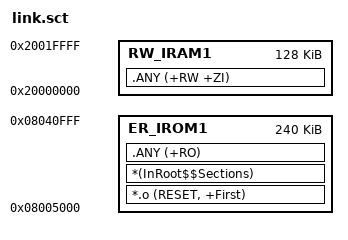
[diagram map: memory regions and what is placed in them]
; Bare-metal blink test — same flash layout as APP
; Bootloader jumps here at 0x08005000

LR_IROM1 0x08005000 0x0003C000  {
  ER_IROM1 0x08005000 0x0003C000  {
   *.o (RESET, +First)
   *(InRoot$$Sections)
   .ANY (+RO)
  }
  RW_IRAM1 0x20000000 0x00020000  {
   .ANY (+RW +ZI)
  }
}
